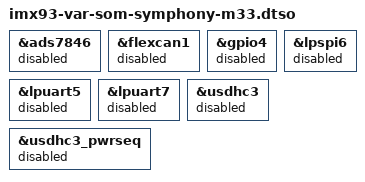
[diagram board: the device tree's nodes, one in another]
// SPDX-License-Identifier: (GPL-2.0+ OR MIT)
/*
 * Cortex-M33 support for Variscite VAR-SOM-MX93 on Symphony-Board
 *
 * Link: https://variscite.com/carrier-boards/symphony-board/
 *
 * Copyright (C) 2026 Variscite Ltd. - https://www.variscite.com/
 *
 */

/dts-v1/;
/plugin/;

#include "imx93-var-common-m33.dtsi"

/* The resistive touchscreen uses GPIO4. */
&ads7846 {
	status = "disabled";
};

/* Reserve the peripherals used by the Cortex-M33 firmware. */
&flexcan1 {
	status = "reserved";
};

&gpio4 {
	status = "reserved";
};

&lpspi6 {
	status = "reserved";
};

/* Disable Bluetooth along with Wi-Fi and release the JTAG pins. */
&lpuart5 {
	status = "disabled";
};

&lpuart7 {
	status = "reserved";
};

/* Wi-Fi reset is connected to GPIO4. */
&usdhc3 {
	status = "disabled";
};

&usdhc3_pwrseq {
	status = "disabled";
};
